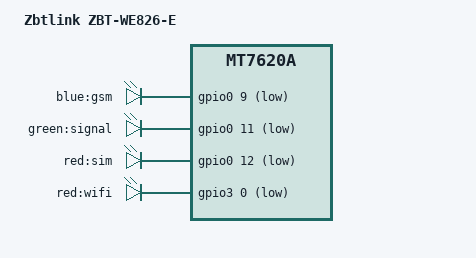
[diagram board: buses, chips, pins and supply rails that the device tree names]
// SPDX-License-Identifier: GPL-2.0-or-later OR MIT

#include "mt7620a_zbtlink_zbt-we826.dtsi"

/ {
	compatible = "zbtlink,zbt-we826-e", "zbtlink,zbt-we826", "ralink,mt7620a-soc";
	model = "Zbtlink ZBT-WE826-E";

	/delete-node/ leds;

	leds {
		compatible = "gpio-leds";

		led_power: gsm {
			label = "blue:gsm";
			gpios = <&gpio0 9 GPIO_ACTIVE_LOW>;
		};

		signal {
			label = "green:signal";
			gpios = <&gpio0 11 GPIO_ACTIVE_LOW>;
		};

		sim {
			label = "red:sim";
			gpios = <&gpio0 12 GPIO_ACTIVE_LOW>;
		};

		air {
			label = "red:wifi";
			gpios = <&gpio3 0 GPIO_ACTIVE_LOW>;
		};
	};
};

&flash0 {
	broken-flash-reset;
};

&firmware {
	reg = <0x50000 0x1fb0000>;
};

&state_default {
	default {
		groups = "i2c", "uartf", "wled";
		function = "gpio";
	};
};
